AUTOSAR XML (schema 4-0-3)
package /ComponentTypes
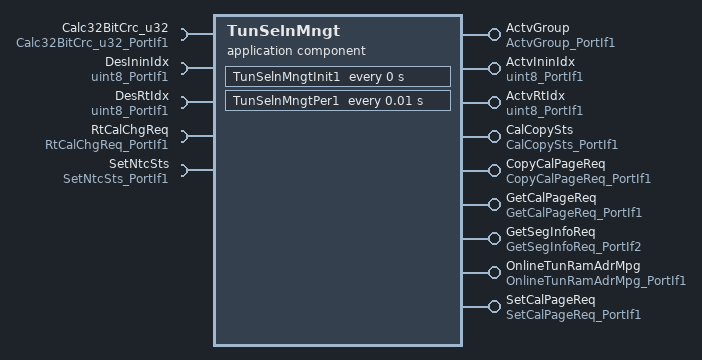
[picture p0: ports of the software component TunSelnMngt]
  application sw component type TunSelnMngt
    9 x provide port:
      ActvGroup: nonqueued-sender-com-spec{data-element=Val, init-value=0}, provided-interface=ActvGroup_PortIf1
      ActvIninIdx: nonqueued-sender-com-spec{data-element=Val, init-value=0}, provided-interface=uint8_PortIf1
      ActvRtIdx: nonqueued-sender-com-spec{data-element=Val, init-value=0}, provided-interface=uint8_PortIf1
      CalCopySts: nonqueued-sender-com-spec{data-element=Val, init-value=0}, provided-interface=CalCopySts_PortIf1
      CopyCalPageReq: server-com-spec{operation=Oper, queue-length=1}, provided-interface=CopyCalPageReq_PortIf1
      GetCalPageReq: server-com-spec{operation=Oper, queue-length=1}, provided-interface=GetCalPageReq_PortIf1
      GetSegInfoReq: server-com-spec{operation=Oper, queue-length=1}, provided-interface=GetSegInfoReq_PortIf2
      OnlineTunRamAdrMpg: server-com-spec{operation=Oper, queue-length=1}, provided-interface=OnlineTunRamAdrMpg_PortIf1
      SetCalPageReq: server-com-spec{operation=Oper, queue-length=1}, provided-interface=SetCalPageReq_PortIf1
    5 x require port:
      Calc32BitCrc_u32: client-com-spec=Oper, required-interface=Calc32BitCrc_u32_PortIf1
      DesIninIdx: nonqueued-receiver-com-spec{data-element=Val, filter=data-filter-type=ALWAYS, init-value=0}, required-interface=uint8_PortIf1
      DesRtIdx: nonqueued-receiver-com-spec{data-element=Val, filter=data-filter-type=ALWAYS, init-value=0}, required-interface=uint8_PortIf1
      RtCalChgReq: client-com-spec=Oper, required-interface=RtCalChgReq_PortIf1
      SetNtcSts: client-com-spec=Oper, required-interface=SetNtcSts_PortIf1
    behavior TunSelnMngt_InternalBehavior
      exclusive area TunSelnMngtIntDataProtnExclsvArea
      ar-typed-per-instance-memorys:
        5 x data:
          OnlineCalSts: type=OnlineCalStsRec1
          PrevActvIninIdx: sw-calibration-access=READ-ONLY, type=uint8
          PrevActvRtIdx: sw-calibration-access=READ-ONLY, type=uint8
          PrevRamPageAcs: sw-calibration-access=READ-ONLY, type=uint8
          RamTblSwt: sw-calibration-access=READ-ONLY, type=uint8
      5 x operation invoked event:
        OIT_CopyCalPageReq_Oper_CopyCalPageReq_Oper: start-on-event=CopyCalPageReq_Oper, operation=CopyCalPageReq.Oper
        OIT_GetCalPageReq_Oper_GetCalPageReq_Oper: start-on-event=GetCalPageReq_Oper, operation=GetCalPageReq.Oper
        OIT_GetSegInfoReq_Oper_GetSegInfoReq_Oper: start-on-event=GetSegInfoReq_Oper, operation=GetSegInfoReq.Oper
        OIT_OnlineTunRamAdrMpg_Oper_OnlineTunRamAdrMpg_Oper: start-on-event=OnlineTunRamAdrMpg_Oper, operation=OnlineTunRamAdrMpg.Oper
        OIT_SetCalPageReq_Oper_SetCalPageReq_Oper: start-on-event=SetCalPageReq_Oper, operation=SetCalPageReq.Oper
      timing event TunSelnMngtInit1_InitEvent: start-on-event=TunSelnMngtInit1, period=0
      timing event TMT_TunSelnMngtPer1: start-on-event=TunSelnMngtPer1, period=0.01
      7 x runnable:
        CopyCalPageReq_Oper: can-enter-exclusive-area=TunSelnMngtIntDataProtnExclsvArea
        GetCalPageReq_Oper
        GetSegInfoReq_Oper
        OnlineTunRamAdrMpg_Oper
        SetCalPageReq_Oper: can-enter-exclusive-area=TunSelnMngtIntDataProtnExclsvArea
        TunSelnMngtInit1
          data-receive-point-by-arguments:
            access REC_DesIninIdx_Val: accessed-variable=DesIninIdx.Val
            access REC_DesRtIdx_Val: accessed-variable=DesRtIdx.Val
          data-send-points:
            access SEND_ActvIninIdx_Val: accessed-variable=ActvIninIdx.Val
            access SEND_ActvRtIdx_Val: accessed-variable=ActvRtIdx.Val
          sync call SC_Calc32BitCrc_u32_Oper: operation=Calc32BitCrc_u32.Oper, timeout=0
          sync call SC_SetNtcSts_Oper: operation=SetNtcSts.Oper, timeout=0
        TunSelnMngtPer1
          data-receive-point-by-arguments:
            access REC_DesRtIdx_Val: accessed-variable=DesRtIdx.Val
          data-send-points:
            access SEND_ActvGroup_Val: accessed-variable=ActvGroup.Val
            access SEND_ActvRtIdx_Val: accessed-variable=ActvRtIdx.Val
            access SEND_CalCopySts_Val: accessed-variable=CalCopySts.Val
          sync call SC_Calc32BitCrc_u32_Oper: operation=Calc32BitCrc_u32.Oper, timeout=0
          sync call SC_RtCalChgReq_Oper: operation=RtCalChgReq.Oper, timeout=0
          sync call SC_SetNtcSts_Oper: operation=SetNtcSts.Oper, timeout=0
  swc implementation TunSelnMngt_Implementation: behavior=TunSelnMngt_InternalBehavior
    code-descriptors:
      code Default: artifact-descriptors=autosar-engineering-object={short-label=Default, category=SWSRC}
